# M4G9 register map
File version: 0.1
Registers are 32-bit, read-write, reset 0x0 unless marked. A register's access mark holds for its fields unless they carry their own. Offsets are from the block's base; [hi:lo] are bit positions; {n}, {i} and the like mark numbered series.

## PN — Port N
Base 0x400E0C00
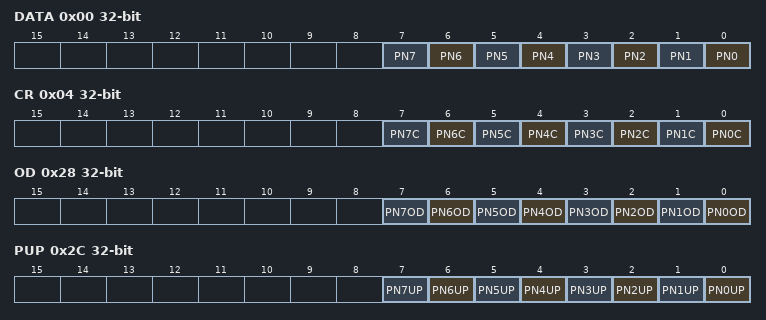
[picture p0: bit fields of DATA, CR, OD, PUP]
0x00 DATA — Port N Data Register
  [n] PN{n} (n=0..7)
0x04 CR — Port N Output Control Register
  [n] PN{n}C (n=0..7)
0x28 OD — Port N Opend Drain Control Register
  [n] PN{n}OD (n=0..7)
0x2C PUP — Port N Pull-up Control Register
  [n] PN{n}UP (n=0..7)
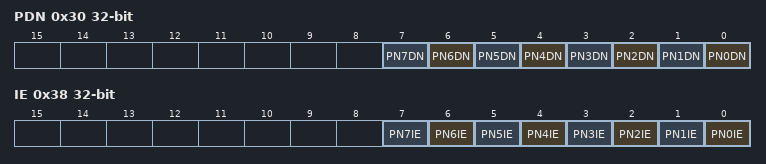
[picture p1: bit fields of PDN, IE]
0x30 PDN — Port N Pull-down Control Register
  [n] PN{n}DN (n=0..7)
0x38 IE — Port N Input Control Register
  [n] PN{n}IE (n=0..7)

## PP — Port P
Base 0x400E0D00
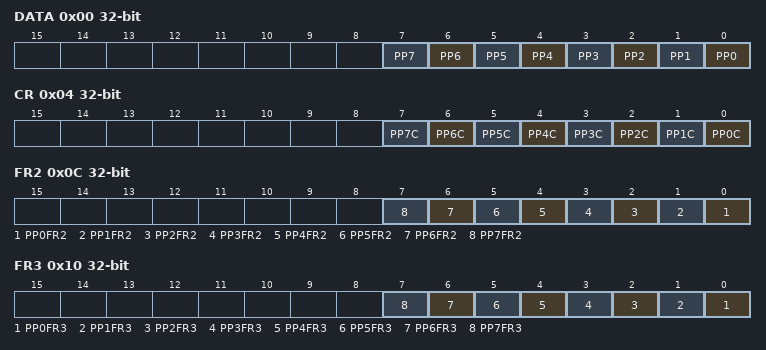
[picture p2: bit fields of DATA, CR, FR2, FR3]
0x00 DATA — Port P Data Register
  [n] PP{n} (n=0..7)
0x04 CR — Port P Output Control Register
  [n] PP{n}C (n=0..7)
0x0C FR2 — Port P Function Register 2
  [n] PP{n}FR2 (n=0..7)
0x10 FR3 — Port P Function Register 3
  [n] PP{n}FR3 (n=0..7)
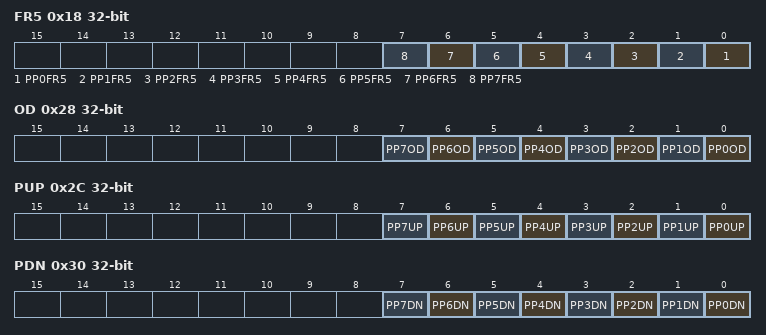
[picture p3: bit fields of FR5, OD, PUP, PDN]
0x18 FR5 — Port P Function Register 5
  [n] PP{n}FR5 (n=0..7)
0x28 OD — Port P Open Drain Control Register
  [n] PP{n}OD (n=0..7)
0x2C PUP — Port P Pull-up Control Register
  [n] PP{n}UP (n=0..7)
0x30 PDN — Port P Pull-down Control Register
  [n] PP{n}DN (n=0..7)
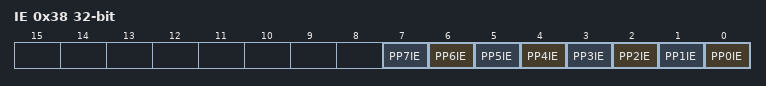
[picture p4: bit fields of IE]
0x38 IE — Port P Input Control Register
  [n] PP{n}IE (n=0..7)

## PR — Port R
Base 0x400E0E00
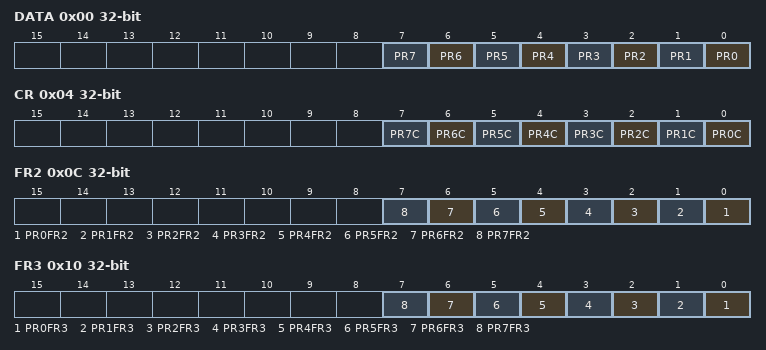
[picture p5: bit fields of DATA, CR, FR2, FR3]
0x00 DATA — Port R Data Register
  [n] PR{n} (n=0..7)
0x04 CR — Port R Output Control Register
  [n] PR{n}C (n=0..7)
0x0C FR2 — Port R Function Register 2
  [n] PR{n}FR2 (n=0..7)
0x10 FR3 — Port R Function Register 3
  [n] PR{n}FR3 (n=0..7)
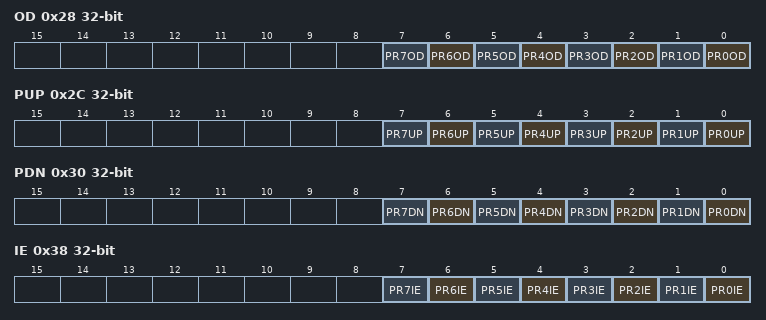
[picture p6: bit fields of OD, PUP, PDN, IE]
0x28 OD — Port R Open Drain Control Register
  [n] PR{n}OD (n=0..7)
0x2C PUP — Port R Pull-up Control Register
  [n] PR{n}UP (n=0..7)
0x30 PDN — Port R Pull-down Control Register
  [n] PR{n}DN (n=0..7)
0x38 IE — Port R Input Control Register
  [n] PR{n}IE (n=0..7)

## PT — Port T
Base 0x400E0F00
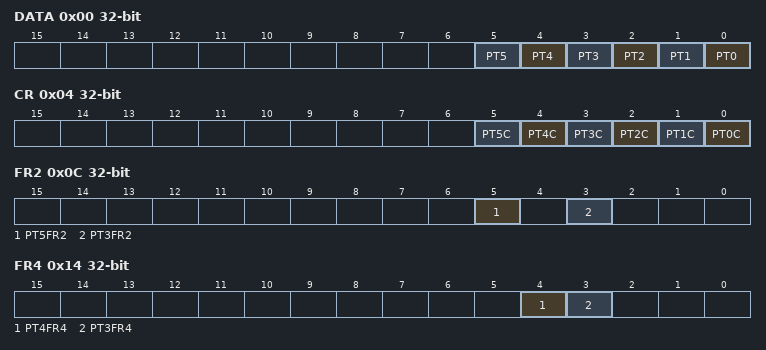
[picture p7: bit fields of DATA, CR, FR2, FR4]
0x00 DATA — Port T Data Register
  [n] PT{n} (n=0..5)
0x04 CR — Port T Output Control Register
  [n] PT{n}C (n=0..5)
0x08 FR1 — Port T Function Register 1
  [3] PT3FR1
0x0C FR2 — Port T Function Register 2
  [5] PT5FR2, [3] PT3FR2
0x10 FR3 — Port T Function Register 3
  [3] PT3FR3
0x14 FR4 — Port T Function Register 4
  [4] PT4FR4, [3] PT3FR4
0x1C FR6 — Port T Function Register 6
  [3] PT3FR6
0x20 FR7 — Port T Function Register 7
  [2] PT2FR7
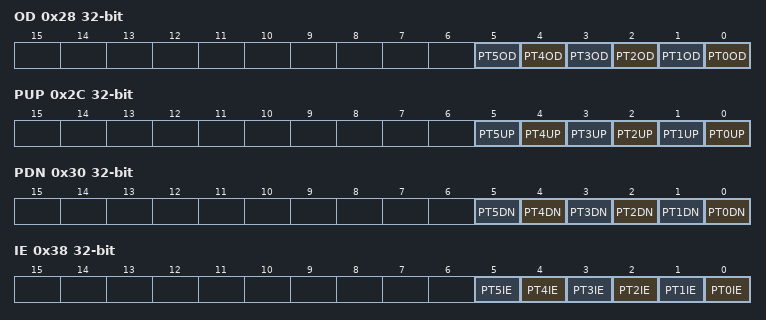
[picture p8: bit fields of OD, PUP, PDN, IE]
0x28 OD — Port T Open Drain Control Register
  [n] PT{n}OD (n=0..5)
0x2C PUP — Port T Pull-up Control Register
  [n] PT{n}UP (n=0..5)
0x30 PDN — Port T Pull-down Control Register
  [n] PT{n}DN (n=0..5)
0x38 IE — Port T Input Control Register
  [n] PT{n}IE (n=0..5)

## PU — Port U
Base 0x400E1000
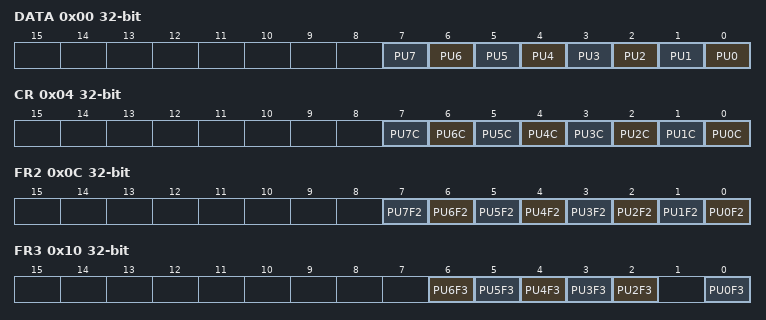
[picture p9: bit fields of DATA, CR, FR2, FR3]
0x00 DATA — Port U Data Register
  [n] PU{n} (n=0..7)
0x04 CR — Port U Output Control Register
  [n] PU{n}C (n=0..7)
0x0C FR2 — Port U Function Register 2
  [n] PU{n}F2 (n=0..7)
0x10 FR3 — Port U Function Register 3
  [n] PU{n}F3 (n=2..6), [0] PU0F3
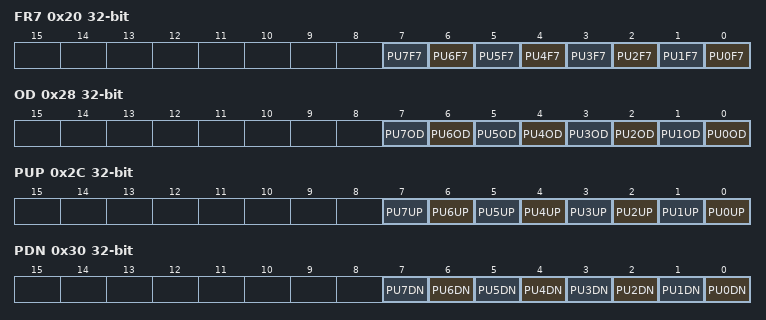
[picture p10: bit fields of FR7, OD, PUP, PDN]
0x20 FR7 — Port U Function Register 7
  [n] PU{n}F7 (n=0..7)
0x28 OD — Port U Open Drain Control Register
  [n] PU{n}OD (n=0..7)
0x2C PUP — Port U Pull-up Control Register
  [n] PU{n}UP (n=0..7)
0x30 PDN — Port U Pull-down Control Register
  [n] PU{n}DN (n=0..7)
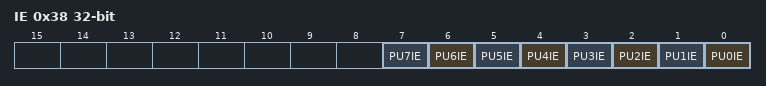
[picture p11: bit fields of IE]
0x38 IE — Port U Input Control Register
  [n] PU{n}IE (n=0..7)

## PV — Port V
Base 0x400E1100
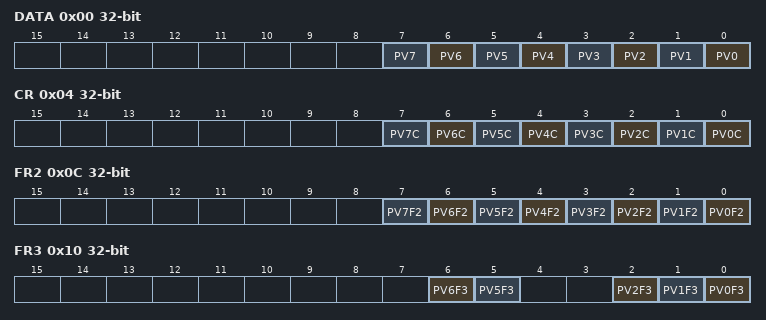
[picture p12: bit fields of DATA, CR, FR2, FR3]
0x00 DATA — Port V Data Register
  [n] PV{n} (n=0..7)
0x04 CR — Port V OutPut Control Register
  [n] PV{n}C (n=0..7)
0x0C FR2 — Port V Function Register 2
  [n] PV{n}F2 (n=0..7)
0x10 FR3 — Port V Function Register 3
  [6] PV6F3, [5] PV5F3, [2] PV2F3, [1] PV1F3, [0] PV0F3
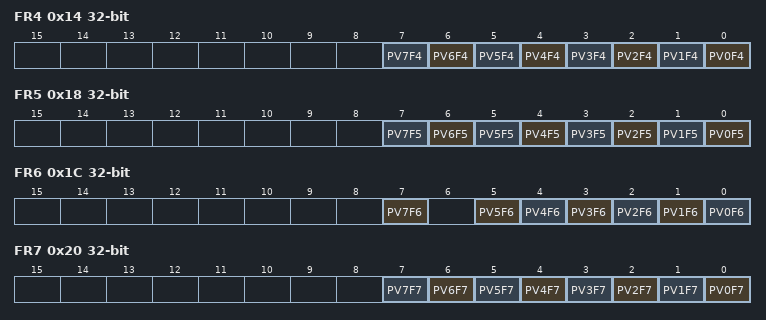
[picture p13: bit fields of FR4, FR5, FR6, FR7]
0x14 FR4 — Port V Function Register 4
  [n] PV{n}F4 (n=0..7)
0x18 FR5 — Port V Function Register 5
  [n] PV{n}F5 (n=0..7)
0x1C FR6 — Port V Function Register 6
  [7] PV7F6, [n] PV{n}F6 (n=0..5)
0x20 FR7 — Port V Function Register 7
  [n] PV{n}F7 (n=0..7)
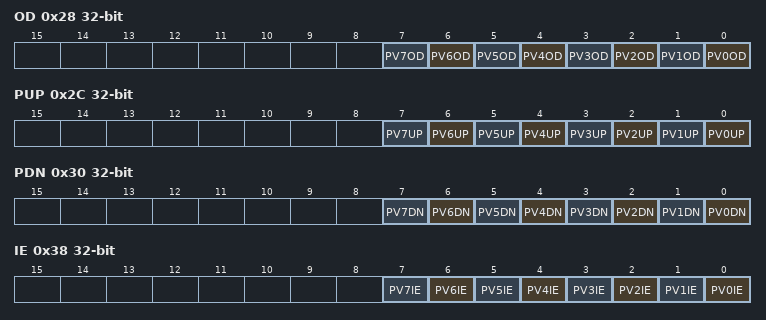
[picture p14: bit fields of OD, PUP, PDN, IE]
0x28 OD — Port V Open Drain Control Register
  [n] PV{n}OD (n=0..7)
0x2C PUP — Port V Pull-up Control Register
  [n] PV{n}UP (n=0..7)
0x30 PDN — Port V Pull-down Control Register
  [n] PV{n}DN (n=0..7)
0x38 IE — Port V InPut Control Register
  [n] PV{n}IE (n=0..7)
